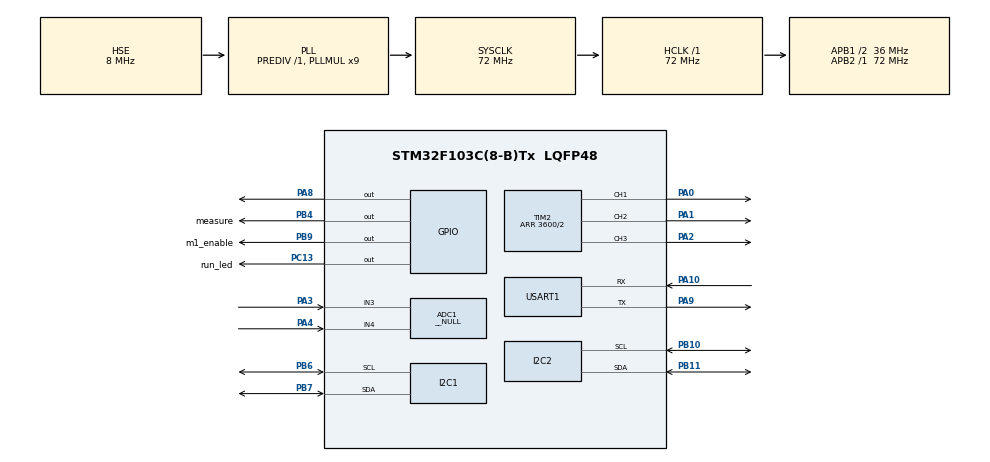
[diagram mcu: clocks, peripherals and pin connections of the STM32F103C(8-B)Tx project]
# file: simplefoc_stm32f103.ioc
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ADC1.Channel-5\#ChannelRegularConversion=ADC_CHANNEL_3
ADC1.Channel-6\#ChannelRegularConversion=ADC_CHANNEL_4
ADC1.ContinuousConvMode=DISABLE
ADC1.DiscontinuousConvMode=ENABLE
ADC1.EnableInjectedConversion=DISABLE
ADC1.EnableRegularConversion=ENABLE
ADC1.InjNumberOfConversion=2
ADC1.Mode=__NULL
ADC1.NbrOfConversion=2
ADC1.NbrOfConversionFlag=1
ADC1.NbrOfDiscConversion=1
ADC1.Rank-5\#ChannelRegularConversion=1
ADC1.Rank-6\#ChannelRegularConversion=2
ADC1.SamplingTime-5\#ChannelRegularConversion=ADC_SAMPLETIME_7CYCLES_5
ADC1.SamplingTime-6\#ChannelRegularConversion=ADC_SAMPLETIME_7CYCLES_5
ADC1.master=1
I2C1.I2C_Mode=I2C_Fast
I2C2.I2C_Mode=I2C_Fast
Mcu.Family=STM32F1
Mcu.Name=STM32F103C(8-B)Tx
Mcu.Package=LQFP48
NVIC.PriorityGroup=NVIC_PRIORITYGROUP_4
NVIC.TIM2_IRQn=true\:0\:0\:false\:false\:true\:true\:true\:true
NVIC.TIM4_IRQn=true\:0\:0\:false\:false\:true\:true\:true\:true
NVIC.USART1_IRQn=true\:0\:0\:false\:false\:true\:true\:true\:true
PA0-WKUP.GPIO_Speed=GPIO_SPEED_FREQ_HIGH
PA0-WKUP.Signal=S_TIM2_CH1_ETR
PA1.GPIO_Speed=GPIO_SPEED_FREQ_HIGH
PA1.Signal=S_TIM2_CH2
PA10.Mode=Asynchronous
PA10.Signal=USART1_RX
PA13.Mode=Serial_Wire
PA13.Signal=SYS_JTMS-SWDIO
PA14.Mode=Serial_Wire
PA14.Signal=SYS_JTCK-SWCLK
PA2.GPIO_Speed=GPIO_SPEED_FREQ_HIGH
PA2.Signal=S_TIM2_CH3
PA3.Signal=ADCx_IN3
PA4.Signal=ADCx_IN4
PA8.Signal=GPIO_Output
PA9.Mode=Asynchronous
PA9.Signal=USART1_TX
PB10.Mode=I2C
PB10.Signal=I2C2_SCL
PB11.Mode=I2C
PB11.Signal=I2C2_SDA
PB4.GPIO_Label=measure
PB4.GPIO_PuPd=GPIO_PULLDOWN
PB4.GPIO_Speed=GPIO_SPEED_FREQ_MEDIUM
PB4.Signal=GPIO_Output
PB6.Mode=I2C
PB6.Signal=I2C1_SCL
PB7.Mode=I2C
PB7.Signal=I2C1_SDA
PB9.GPIO_Label=m1_enable
PB9.GPIO_PuPd=GPIO_PULLDOWN
PB9.GPIO_Speed=GPIO_SPEED_FREQ_MEDIUM
PB9.Signal=GPIO_Output
PC13-TAMPER-RTC.GPIO_Label=run_led
PC13-TAMPER-RTC.GPIO_PuPd=GPIO_PULLDOWN
PC13-TAMPER-RTC.GPIO_Speed=GPIO_SPEED_FREQ_LOW
PC13-TAMPER-RTC.Signal=GPIO_Output
PD0-OSC_IN.Mode=HSE-External-Oscillator
PD0-OSC_IN.Signal=RCC_OSC_IN
PD1-OSC_OUT.Mode=HSE-External-Oscillator
PD1-OSC_OUT.Signal=RCC_OSC_OUT
ProjectManager.HeapSize=0x200
ProjectManager.StackSize=0x400
ProjectManager.TargetToolchain=MDK-ARM V5.32
RCC.ADCPresc=RCC_ADCPCLK2_DIV6
RCC.AHBFreq_Value=72000000
RCC.APB1CLKDivider=RCC_HCLK_DIV2
RCC.APB1Freq_Value=36000000
RCC.APB1TimFreq_Value=72000000
RCC.APB2Freq_Value=72000000
RCC.APB2TimFreq_Value=72000000
RCC.HCLKFreq_Value=72000000
RCC.PLLMUL=RCC_PLL_MUL9
RCC.PLLSourceVirtual=RCC_PLLSOURCE_HSE
RCC.SYSCLKFreq_VALUE=72000000
RCC.SYSCLKSource=RCC_SYSCLKSOURCE_PLLCLK
RCC.USBFreq_Value=72000000
SH.ADCx_IN3.0=ADC1_IN3,IN3
SH.ADCx_IN4.0=ADC1_IN4,IN4
SH.S_TIM2_CH1_ETR.0=TIM2_CH1,PWM Generation1 CH1
SH.S_TIM2_CH2.0=TIM2_CH2,PWM Generation2 CH2
SH.S_TIM2_CH3.0=TIM2_CH3,PWM Generation3 CH3
TIM2.AutoReloadPreload=TIM_AUTORELOAD_PRELOAD_ENABLE
TIM2.Channel-PWM\ Generation1\ CH1=TIM_CHANNEL_1
TIM2.Channel-PWM\ Generation2\ CH2=TIM_CHANNEL_2
TIM2.Channel-PWM\ Generation3\ CH3=TIM_CHANNEL_3
TIM2.CounterMode=TIM_COUNTERMODE_CENTERALIGNED1
TIM2.OCMode_PWM-PWM\ Generation1\ CH1=TIM_OCMODE_PWM2
TIM2.OCMode_PWM-PWM\ Generation2\ CH2=TIM_OCMODE_PWM2
TIM2.OCMode_PWM-PWM\ Generation3\ CH3=TIM_OCMODE_PWM2
TIM2.Period=3600/2
TIM2.Pulse-PWM\ Generation1\ CH1=1800
TIM2.Pulse-PWM\ Generation2\ CH2=1800
TIM2.Pulse-PWM\ Generation3\ CH3=1800
TIM2.TIM_MasterOutputTrigger=TIM_TRGO_UPDATE
TIM4.AutoReloadPreload=TIM_AUTORELOAD_PRELOAD_ENABLE
TIM4.Period=500-1
TIM4.Prescaler=72-1
USART1.VirtualMode=VM_ASYNC
VP_TIM2_VS_ClockSourceINT.Mode=Internal
VP_TIM4_VS_ClockSourceINT.Mode=Internal
board=custom

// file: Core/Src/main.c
/* USER CODE BEGIN Header */
/**
  ******************************************************************************
  * @file           : main.c
  * @brief          : Main program body
  ******************************************************************************
  * @attention
  *
  * Copyright (c) 2024 STMicroelectronics.
  * All rights reserved.
  *
  * This software is licensed under terms that can be found in the LICENSE file
  * in the root directory of this software component.
  * If no LICENSE file comes with this software, it is provided AS-IS.
  *
  ******************************************************************************
  */
/* USER CODE END Header */
#include "main.h"
#include "adc.h"
#include "i2c.h"
#include "tim.h"
#include "usart.h"
#include "gpio.h"

/* USER CODE BEGIN Includes */
#include "user_main.h"
/* USER CODE END Includes */

void SystemClock_Config(void);

/* USER CODE BEGIN 0 */

//const u8 TEXT_Buffer_1[]={0x11, 0x22, 0x33};//要写入到STM32 FLASH的字符串数组
//#define SIZE sizeof(TEXT_Buffer_1)	 	//数组长度
//u8 datatemp[SIZE];  //Flash读取缓存数组

/**
 * @brief RTTͨ��0��ӡ������
 *
 * @param value
 */
void SEGGER_Printf_Float(float value){
    char buffer[50] = {0,};
    sprintf(buffer, "%.4f\n", value); // ��ʽ��Ϊ�ַ���
    SEGGER_RTT_printf(0, "%s", buffer); // ��ӡ�ַ���
}
/* USER CODE END 0 */

int main(void)
{

  /* MCU Configuration--------------------------------------------------------*/

  /* Reset of all peripherals, Initializes the Flash interface and the Systick. */
  HAL_Init();

  /* Configure the system clock */
  SystemClock_Config();

  /* Initialize all configured peripherals */
  MX_GPIO_Init();
  MX_I2C1_Init();
  MX_I2C2_Init();
  MX_TIM2_Init();
  MX_TIM4_Init();
  MX_ADC1_Init();
  MX_USART1_UART_Init();
  /* USER CODE BEGIN 2 */
//	STMFLASH_Write(FLASH_SAVE_ADDR,(u16*)TEXT_Buffer_1,SIZE);//第一次写读
//	STMFLASH_Read(FLASH_SAVE_ADDR,(u16*)datatemp,SIZE);

//  DWT_Timer_Init(); // ��ʼ��DWT��ʱ��
  main_Cpp();       // ��תC++����
  /* USER CODE END 2 */

  /* Infinite loop */
  /* USER CODE BEGIN WHILE */
  while (1)
  {
//			uint8_t UART_BUF[12] = "you press A!";
//			HAL_GPIO_WritePin(GPIOA,GPIO_PIN_8,GPIO_PIN_SET);
//			HAL_UART_Transmit(&huart1,UART_BUF,12,0xffff);
//			HAL_GPIO_WritePin(GPIOA,GPIO_PIN_8,GPIO_PIN_RESET);
//			HAL_GPIO_WritePin(GPIOA,GPIO_PIN_8,GPIO_PIN_SET);
//			HAL_UART_Transmit_IT(&huart1,UART_BUF,12);
//			HAL_GPIO_WritePin(GPIOA,GPIO_PIN_8,GPIO_PIN_RESET);
    /* USER CODE END WHILE */

  }
}

void SystemClock_Config(void)
{
  RCC_OscInitTypeDef RCC_OscInitStruct = {0};
  RCC_ClkInitTypeDef RCC_ClkInitStruct = {0};
  RCC_PeriphCLKInitTypeDef PeriphClkInit = {0};

  /** Initializes the RCC Oscillators according to the specified parameters
  * in the RCC_OscInitTypeDef structure.
  */
  RCC_OscInitStruct.OscillatorType = RCC_OSCILLATORTYPE_HSE;
  RCC_OscInitStruct.HSEState = RCC_HSE_ON;
  RCC_OscInitStruct.HSEPredivValue = RCC_HSE_PREDIV_DIV1;
  RCC_OscInitStruct.HSIState = RCC_HSI_ON;
  RCC_OscInitStruct.PLL.PLLState = RCC_PLL_ON;
  RCC_OscInitStruct.PLL.PLLSource = RCC_PLLSOURCE_HSE;
  RCC_OscInitStruct.PLL.PLLMUL = RCC_PLL_MUL9;
  if (HAL_RCC_OscConfig(&RCC_OscInitStruct) != HAL_OK)
  {
    Error_Handler();
  }

  /** Initializes the CPU, AHB and APB buses clocks
  */
  RCC_ClkInitStruct.ClockType = RCC_CLOCKTYPE_HCLK|RCC_CLOCKTYPE_SYSCLK
                              |RCC_CLOCKTYPE_PCLK1|RCC_CLOCKTYPE_PCLK2;
  RCC_ClkInitStruct.SYSCLKSource = RCC_SYSCLKSOURCE_PLLCLK;
  RCC_ClkInitStruct.AHBCLKDivider = RCC_SYSCLK_DIV1;
  RCC_ClkInitStruct.APB1CLKDivider = RCC_HCLK_DIV2;
  RCC_ClkInitStruct.APB2CLKDivider = RCC_HCLK_DIV1;

  if (HAL_RCC_ClockConfig(&RCC_ClkInitStruct, FLASH_LATENCY_2) != HAL_OK)
  {
    Error_Handler();
  }
  PeriphClkInit.PeriphClockSelection = RCC_PERIPHCLK_ADC;
  PeriphClkInit.AdcClockSelection = RCC_ADCPCLK2_DIV6;
  if (HAL_RCCEx_PeriphCLKConfig(&PeriphClkInit) != HAL_OK)
  {
    Error_Handler();
  }
}

void Error_Handler(void)
{
  __disable_irq();
  while (1)
  {
  }
}
